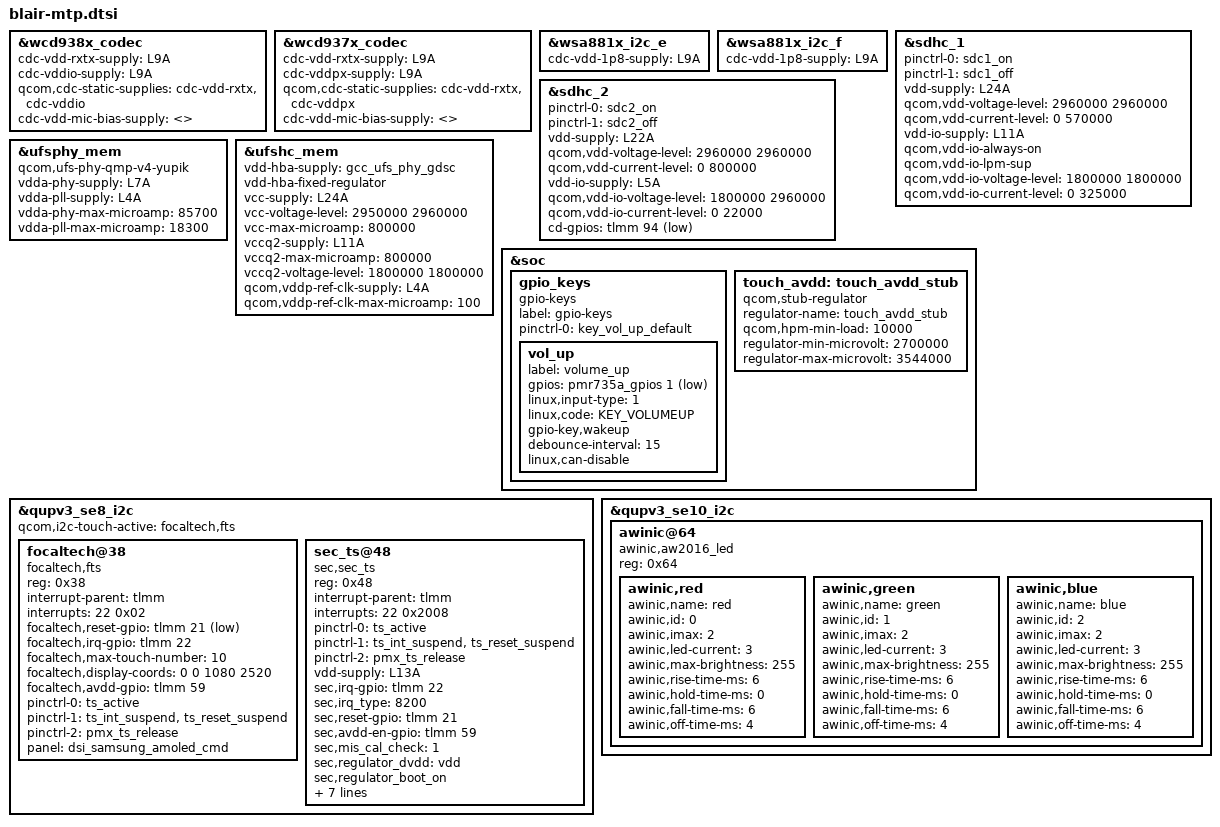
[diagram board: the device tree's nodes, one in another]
#include "holi-audio-overlay.dtsi"
#include <dt-bindings/gpio/gpio.h>
#include <dt-bindings/input/linux-event-codes.h>
#include "holi-pmic-overlay-pm6125.dtsi"
#include "holi-thermal-overlay-pm6125.dtsi"
#include "display/holi-sde-display-mtp-pm6125.dtsi"
#include "display/blair-sde-display-mtp.dtsi"
#include "blair-fingerprint.dtsi"



&wcd938x_codec {
	cdc-vdd-rxtx-supply = <&L9A>;
	cdc-vddio-supply = <&L9A>;
	qcom,cdc-static-supplies = "cdc-vdd-rxtx",
				   "cdc-vddio";
	/*
	 * Overriding cdc-vdd-mic-bias-supply to dummy value
	 * to avoid compilation errors as BOB is not definied
	 * for pm6125
	 */
	cdc-vdd-mic-bias-supply = <>;
};

&wcd937x_codec {
	cdc-vdd-rxtx-supply = <&L9A>;
	cdc-vddpx-supply = <&L9A>;
	qcom,cdc-static-supplies = "cdc-vdd-rxtx",
				   "cdc-vddpx";
	/*
	 * Overriding cdc-vdd-mic-bias-supply to dummy value
	 * to avoid compilation errors as BOB is not definied
	 * for pm6125
	 */
	cdc-vdd-mic-bias-supply = <>;
};

&wsa881x_i2c_e {
	cdc-vdd-1p8-supply = <&L9A>;
};

&wsa881x_i2c_f {
	cdc-vdd-1p8-supply = <&L9A>;
};

/* Dummy LDO reference */
&sdhc_1 {
	status = "ok";

	pinctrl-names = "default", "sleep";
	pinctrl-0 = <&sdc1_on>;
	pinctrl-1 = <&sdc1_off>;

	vdd-supply = <&L24A>;
	qcom,vdd-voltage-level = <2960000 2960000>;
	qcom,vdd-current-level = <0 570000>;

	vdd-io-supply = <&L11A>;
	qcom,vdd-io-always-on;
	qcom,vdd-io-lpm-sup;
	qcom,vdd-io-voltage-level = <1800000 1800000>;
	qcom,vdd-io-current-level = <0 325000>;
};

&sdhc_2 {
	status = "ok";

	pinctrl-names = "default", "sleep";
	pinctrl-0 = <&sdc2_on>;
	pinctrl-1 = <&sdc2_off>;

	vdd-supply = <&L22A>;
	qcom,vdd-voltage-level = <2960000 2960000>;
	qcom,vdd-current-level = <0 800000>;

	vdd-io-supply = <&L5A>;
	qcom,vdd-io-voltage-level = <1800000 2960000>;
	qcom,vdd-io-current-level = <0 22000>;

	cd-gpios = <&tlmm 94 GPIO_ACTIVE_LOW>;
};

&ufsphy_mem {
		compatible = "qcom,ufs-phy-qmp-v4-yupik";

		vdda-phy-supply = <&L7A>;
		vdda-pll-supply = <&L4A>;
		vdda-phy-max-microamp = <85700>;
		vdda-pll-max-microamp = <18300>;

		status = "ok";
};

&ufshc_mem {
		vdd-hba-supply = <&gcc_ufs_phy_gdsc>;
		vdd-hba-fixed-regulator;

		vcc-supply = <&L24A>;
		vcc-voltage-level = <2950000 2960000>;
		vcc-max-microamp = <800000>;

		vccq2-supply = <&L11A>;
		vccq2-max-microamp = <800000>;
		vccq2-voltage-level = <1800000 1800000>;

		qcom,vddp-ref-clk-supply = <&L4A>;
		qcom,vddp-ref-clk-max-microamp = <100>;

		status = "ok";
};


&soc {
	gpio_keys {
		compatible = "gpio-keys";
		label = "gpio-keys";

		pinctrl-names = "default";
		pinctrl-0 = <&key_vol_up_default>;

		vol_up {
			label = "volume_up";
			gpios = <&pmr735a_gpios 1 GPIO_ACTIVE_LOW>;
			linux,input-type = <1>;
			linux,code = <KEY_VOLUMEUP>;
			gpio-key,wakeup;
			debounce-interval = <15>;
			linux,can-disable;
		};
	};
};

&soc {
	touch_avdd: touch_avdd_stub {
		/*
		 * Touch eLDO controlled by gpio#53 is always ON.
		 * Using dummy regulator.
		 */
		compatible = "qcom,stub-regulator";
		regulator-name = "touch_avdd_stub";
		qcom,hpm-min-load = <10000>;
		regulator-min-microvolt = <2700000>;
		regulator-max-microvolt = <3544000>;
	};
};

&qupv3_se8_i2c {
 status = "okay";
 qcom,i2c-touch-active="focaltech,fts";
focaltech@38{ 
   compatible = "focaltech,fts"; 
   reg = <0x38>;       
   interrupt-parent = <&tlmm>;
   interrupts = <22 0x02>;
   //vdd-supply = <&L13A>;
            //vcc_i2c-supply = <&pm8916_l16>;
   focaltech,reset-gpio = <&tlmm 21 0x01>;
   focaltech,irq-gpio = <&tlmm 22 0x02>; 
   focaltech,max-touch-number = <10>;   
   focaltech,display-coords =  <0 0 1080 2520>;  
   focaltech,avdd-gpio = <&tlmm 59 0x0>;
   pinctrl-names = "pmx_ts_active","pmx_ts_suspend","pmx_ts_release";
   pinctrl-0 = <&ts_active>;
   pinctrl-1 = <&ts_int_suspend &ts_reset_suspend>;
   pinctrl-2 = <&pmx_ts_release>;

   //focaltech,regulator_dvdd = "vdd";
   /*
   focaltech,have-key;
   focaltech,key-number = <3>; 
   focaltech,keys = <139 102 158>;  
   focaltech,key-x-coords = <200 600 800>;
   focaltech,key-y-coords = <2000 2000 2000>; 
   */
   panel = <&dsi_samsung_amoled_cmd>;
  };
	sec_ts@48 {
		compatible = "sec,sec_ts";
		reg = <0x48>;
		interrupt-parent = <&tlmm>;
		interrupts = <22 0x2008>;
		pinctrl-names = "pmx_ts_active","pmx_ts_suspend",
					"pmx_ts_release";
		pinctrl-0 = <&ts_active>;
		pinctrl-1 = <&ts_int_suspend &ts_reset_suspend>;
		pinctrl-2 = <&pmx_ts_release>;
		vdd-supply = <&L13A>;
		//avdd-supply = <&L6A>;
		sec,irq-gpio = <&tlmm 22 0x2008>;
		sec,irq_type = <8200>;
		sec,reset-gpio = <&tlmm 21 0x00>;
		sec,avdd-en-gpio = <&tlmm 59 0x00>;
		sec,mis_cal_check = <1>;
		sec,regulator_dvdd = "vdd";
		//sec,regulator_avdd = "avdd";
		sec,regulator_boot_on;
		sec,i2c-burstmax = <32>;
		sec,project_name = "PJT", "MODEL";
		sec,max_coords = <1080 2520>;
		sec,always_lpmode = <0>;
		sec,bringup = <0>;
		sec,firmware_name = "s6sy761_p213.bin";

		panel = <&dsi_samsung_amoled_cmd>;
	};
};

&qupv3_se10_i2c {
	awinic@64 {
		compatible = "awinic,aw2016_led";
		reg = <0x64>;

		awinic,red {
			awinic,name = "red";
			awinic,id = <0>;
			awinic,imax = <2>;
			awinic,led-current = <3>;
			awinic,max-brightness = <255>;
			awinic,rise-time-ms = <6>;
			awinic,hold-time-ms = <0>;
			awinic,fall-time-ms = <6>;
			awinic,off-time-ms = <4>;
		};

		awinic,green {
			awinic,name = "green";
			awinic,id = <1>;
			awinic,imax = <2>;
			awinic,led-current = <3>;
			awinic,max-brightness = <255>;
			awinic,rise-time-ms = <6>;
			awinic,hold-time-ms = <0>;
			awinic,fall-time-ms = <6>;
			awinic,off-time-ms = <4>;
		};

		awinic,blue {
			awinic,name = "blue";
			awinic,id = <2>;
			awinic,imax = <2>;
			awinic,led-current = <3>;
			awinic,max-brightness = <255>;
			awinic,rise-time-ms = <6>;
			awinic,hold-time-ms = <0>;
			awinic,fall-time-ms = <6>;
			awinic,off-time-ms = <4>;
		};

	};
};

#include "camera/blair-camera-sensor-mtp.dtsi"

